# ATSAM4LS4A register map
Vendor: Atmel Corporation; Series: SAM4L; File version: B
CPU: CM4 r0p1, little endian, MPU, no FPU, 4 interrupt priority bits
Registers are 32-bit, write-only, reset 0x0 unless marked. A register's access mark holds for its fields unless they carry their own. Offsets are from the block's base; [hi:lo] are bit positions; {n}, {i} and the like mark numbered series; 'fields as' and 'values as' point back to an identical list.

## HFLASHC — Flash Controller
Base 0x400A0000; register names take the prefix FLASHCALW_
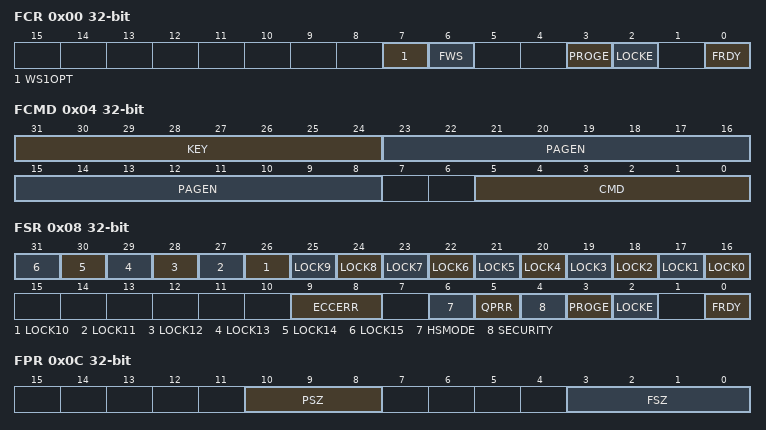
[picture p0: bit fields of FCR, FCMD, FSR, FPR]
0x00 FCR rw — Flash Controller Control Register
  [7] WS1OPT — Wait State 1 Optimization
  [6] FWS — Flash Wait State
    0=The flash is read with 0 wait states; 1=The flash is read with 1 wait states
  [3] PROGE — Programming Error Interrupt Enable
    0=Programming Error does not generate an interrupt; 1=Programming Error generates an interrupt
  [2] LOCKE — Lock Error Interrupt Enable
    0=Lock Error does not generate an interrupt; 1=Lock Error generates an interrupt
  [0] FRDY — Flash Ready Interrupt Enable
    0=Flash Ready does not generate an interrupt; 1=Flash Ready generates an interrupt
0x04 FCMD rw — Flash Controller Command Register
  [31:24] KEY — Write protection key
    165=KEY
  [23:8] PAGEN — Page number
  [5:0] CMD — Command
    0=NOP (No Operation); 1=WP (Write Page); 2=EP (Erase Page); 3=CPB (Clear Page Buffer); 4=LP (Lock Region containing page); 5=UP (Unlock Region containing page); 6=EA (Erase All, including secuity and fuse bits); 7=WGPB (Write General-Purpose fuse Bit); 8=EGPB (Erase General-Purpose fuse Bit); 9=SSB (Set Security Bit); 10=PGPFB (Program GPFuse Byte); 11=EAGPF (Erase All GP Fuses); 12=QPR (Quick Page Read); 13=WUP (Write User Page); 14=EUP (Erase User Page); 15=QPRUP (Quick Page Read User Page); 16=HSEN (High Speed Mode Enable); 17=HSDIS (High Speed Mode Disable)
0x08 FSR rw — Flash Controller Status Register
  [n+16] LOCK{n} ro (n=0..15) — Lock Region {n} Lock Status
  [9:8] ECCERR ro — ECC Error Status
    0=NOERROR; 1=ONEECCERR (one ECC error detected); 2=TWOECCERR (two ECC errors detected)
  [6] HSMODE ro — High Speed Mode
  [5] QPRR ro — Quick Page Read Result
  [4] SECURITY ro — Security Bit Status
  [3] PROGE ro — Programming Error Status
  [2] LOCKE ro — Lock Error Status
  [0] FRDY ro — Flash Ready Status
0x0C FPR ro — Flash Controller Parameter Register
  [10:8] PSZ — Page Size
  [3:0] FSZ — Flash Size
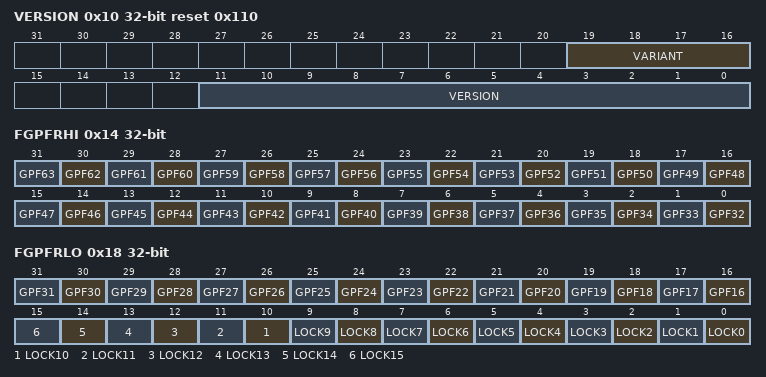
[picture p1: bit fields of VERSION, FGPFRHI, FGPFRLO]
0x10 VERSION ro reset 0x110 — Flash Controller Version Register
  [19:16] VARIANT — Variant Number
  [11:0] VERSION — Version Number
0x14 FGPFRHI rw — Flash Controller General Purpose Fuse Register High
  [n-32] GPF{n} ro (n=32..63) — General Purpose Fuse {n}
0x18 FGPFRLO rw — Flash Controller General Purpose Fuse Register Low
  [n] GPF{n} ro (n=16..31) — General Purpose Fuse {n}
  [n] LOCK{n} ro (n=0..15) — Lock Bit {n}

## FREQM — Frequency Meter
Base 0x400E0C00; register names take the prefix FREQM_
0x00 CTRL — Control register
  [0] START — Start frequency measurement
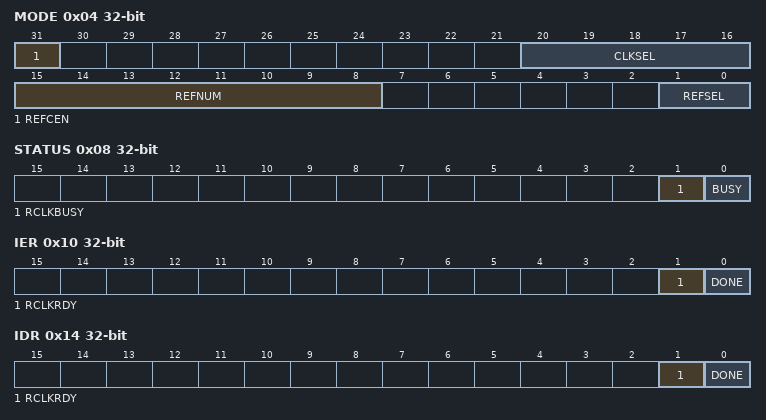
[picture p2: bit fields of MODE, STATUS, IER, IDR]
0x04 MODE rw
  [31] REFCEN — Reference Clock Enable
  [20:16] CLKSEL — Clock Source Selection
  [15:8] REFNUM — Number of Reference CLock Cycles
  [1:0] REFSEL — Reference Clock Selection
0x08 STATUS ro
  [1] RCLKBUSY — Reference Clock busy
  [0] BUSY — Frequency measurement on-going
0x0C VALUE ro
  [23:0] VALUE — Measured frequency
0x10 IER — Interrupt Enable Register
  [1] RCLKRDY — Reference Clock ready
  [0] DONE — Frequency measurment done
0x14 IDR — Interrupt Diable Register
  fields as IER
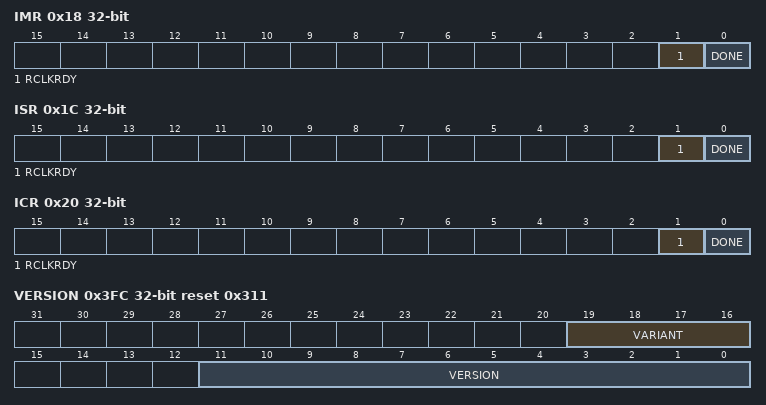
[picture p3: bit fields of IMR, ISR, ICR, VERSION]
0x18 IMR ro — Interrupt Mask Register
  fields as IER
0x1C ISR ro — Interrupt Status Register
  fields as IER
0x20 ICR — Interrupt Clear Register
  fields as IER
0x3FC VERSION ro reset 0x311
  [19:16] VARIANT — Variant number
  [11:0] VERSION — Version number

## GLOC — Glue Logic Controller
Base 0x40060000; register names take the prefix GLOC_
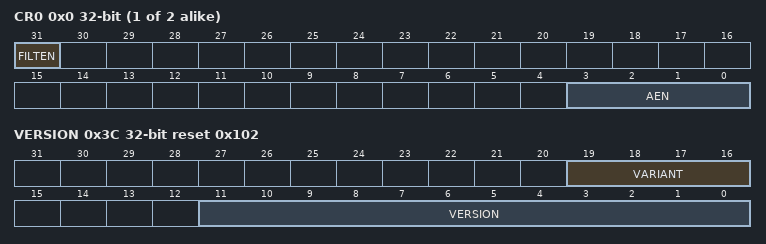
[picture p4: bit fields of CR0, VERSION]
{0x0+8i} CR{i} (i=0..1) rw — Control Register
  [31] FILTEN — Filter enable
  [3:0] AEN — Input mask
{0x4+8i} TRUTH{i} (i=0..1) rw
  [15:0] TRUTH
0x38 PARAMETER ro
  [7:0] LUTS
0x3C VERSION ro reset 0x102
  [19:16] VARIANT, [11:0] VERSION

## Notices in the file
Atmel Microcontroller Software Support
Copyright (c) 2014, Atmel Corporation
All rights reserved.
Redistribution and use in source and binary forms, with or without
modification, are permitted provided that the following condition is met:
- Redistributions of source code must retain the above copyright notice,
this list of conditions and the disclaimer below.
Atmel's name may not be used to endorse or promote products derived from
this software without specific prior written permission.
DISCLAIMER: THIS SOFTWARE IS PROVIDED BY ATMEL "AS IS" AND ANY EXPRESS OR
IMPLIED WARRANTIES, INCLUDING, BUT NOT LIMITED TO, THE IMPLIED WARRANTIES OF
MERCHANTABILITY, FITNESS FOR A PARTICULAR PURPOSE AND NON-INFRINGEMENT ARE
DISCLAIMED. IN NO EVENT SHALL ATMEL BE LIABLE FOR ANY DIRECT, INDIRECT,
INCIDENTAL, SPECIAL, EXEMPLARY, OR CONSEQUENTIAL DAMAGES (INCLUDING, BUT NOT
LIMITED TO, PROCUREMENT OF SUBSTITUTE GOODS OR SERVICES; LOSS OF USE, DATA,
OR PROFITS; OR BUSINESS INTERRUPTION) HOWEVER CAUSED AND ON ANY THEORY OF
LIABILITY, WHETHER IN CONTRACT, STRICT LIABILITY, OR TORT (INCLUDING
NEGLIGENCE OR OTHERWISE) ARISING IN ANY WAY OUT OF THE USE OF THIS SOFTWARE,
EVEN IF ADVISED OF THE POSSIBILITY OF SUCH DAMAGE.
